// Description: LIN Description file created using Vector's DaVinci Network Designer

// Created: 02 Oct 2007 09:21:55

// Author: Vector Informatik GmbH

// Version: 0.1

LIN_description_file;
LIN_protocol_version = "2.2";
LIN_language_version = "2.2";
LIN_speed = 19.2 kbps;

Nodes {
  Master: SeatECU, 1 ms, 0.2 ms ;
  Slaves: Motor1, Motor2 ;
}

Signals {
  Motor1ErrorCode: 8, 5, Motor1, SeatECU ;
  Motor1ErrorValue: 8, 1, Motor1, SeatECU ;
  Motor1LinError: 1, 0, Motor1, SeatECU ;
  Motor1Position: 32, {0, 0, 0, 0}, Motor1, SeatECU ;
  Motor1Temp: 8, 5, Motor1, SeatECU ;
  Motor2ErrorCode: 8, 2, Motor2, SeatECU ;
  Motor2ErrorValue: 8, 4, Motor2, SeatECU ;
  Motor2LinError: 1, 0, Motor2, SeatECU ;
  Motor2Position: 32, {0, 0, 0, 0}, Motor2, SeatECU ;
  Motor2Temp: 8, 5, Motor2, SeatECU ;
  MotorDirection: 2, 0, SeatECU, Motor1, Motor2 ;
  MotorSelection: 4, 0, SeatECU, Motor1, Motor2 ;
  MotorSpeed: 10, 0, SeatECU, Motor1, Motor2 ;
}

Frames {
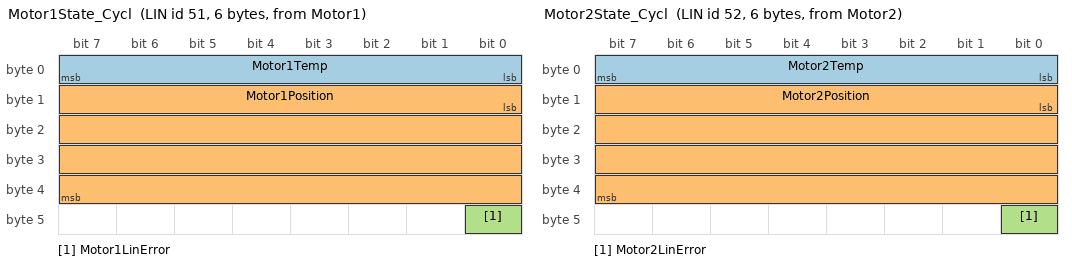
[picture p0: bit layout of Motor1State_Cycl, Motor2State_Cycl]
  Motor1State_Cycl: 51, Motor1, 6 {
    Motor1Temp, 0 ;
    Motor1Position, 8 ;
    Motor1LinError, 40 ;
  }
  Motor1State_Event: 54, Motor1, 3 {
    Motor1ErrorCode, 8 ;
    Motor1ErrorValue, 16 ;
  }
  Motor2State_Cycl: 52, Motor2, 6 {
    Motor2Temp, 0 ;
    Motor2Position, 8 ;
    Motor2LinError, 40 ;
  }
  Motor2State_Event: 55, Motor2, 3 {
    Motor2ErrorCode, 8 ;
    Motor2ErrorValue, 16 ;
  }
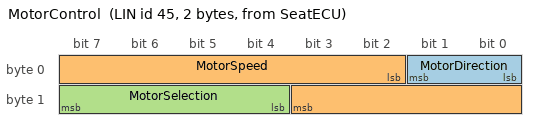
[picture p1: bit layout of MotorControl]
  MotorControl: 45, SeatECU, 2 {
    MotorDirection, 0 ;
    MotorSpeed, 2 ;
    MotorSelection, 12 ;
  }
}

Sporadic_frames {
  SporadicPollingFrame: MotorControl ;
}

Event_triggered_frames {
  ETF_MotorStates: CollisionResolutionTable, 58, Motor1State_Event, Motor2State_Event ;
}

Node_attributes {
  Motor1{
    LIN_protocol = "2.2" ;
    configured_NAD = 0x2 ;
    product_id = 0x1E, 0x1, 0 ;
    response_error = Motor1LinError ;
    P2_min = 100 ms ;
    ST_min = 20 ms ;
    configurable_frames {
      MotorControl ;
      Motor1State_Cycl ;
      Motor1State_Event ;
      ETF_MotorStates ;
    }
  }
  Motor2{
    LIN_protocol = "2.2" ;
    configured_NAD = 0x3 ;
    product_id = 0x1E, 0x1, 0 ;
    response_error = Motor2LinError ;
    P2_min = 100 ms ;
    ST_min = 20 ms ;
    configurable_frames {
      MotorControl ;
      Motor2State_Cycl ;
      Motor2State_Event ;
      ETF_MotorStates ;
    }
  }
}

Schedule_tables {
 NormalTable {
    MotorControl delay 10 ms ;
    Motor1State_Cycl delay 10 ms ;
    Motor2State_Cycl delay 10 ms ;
  }
 NormalTableSporadic {
    Motor1State_Cycl delay 50 ms ;
    Motor2State_Cycl delay 50 ms ;
    SporadicPollingFrame delay 50 ms ;
  }
 NormalTableEvent {
    Motor1State_Cycl delay 50 ms ;
    Motor2State_Cycl delay 50 ms ;
    ETF_MotorStates delay 50 ms ;
  }
 InitTable {
    AssignFrameId { Motor1, Motor1State_Cycl } delay 10 ms ;
    AssignFrameId { Motor2, Motor2State_Cycl } delay 10 ms ;
    AssignFrameId { Motor1, Motor1State_Event } delay 10 ms ;
    AssignFrameId { Motor2, Motor2State_Event } delay 10 ms ;
  }
  CollisionResolutionTable {
    Motor1State_Event delay 10 ms ;
  Motor2State_Event delay 10 ms ;
  }
}

Signal_encoding_types {
  encTemperature {
    physical_value, 5, 100, 2, 20, "Degree" ;
  }
  MotorSpeed {
    physical_value, 0, 0, 1, 0, "rpm" ;
  }
}

Signal_representation {
  encTemperature: Motor1Temp, Motor2Temp ;
  MotorSpeed: MotorSpeed ;
}
